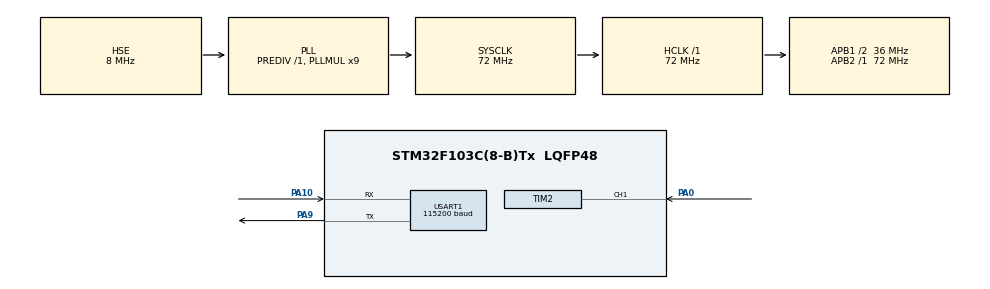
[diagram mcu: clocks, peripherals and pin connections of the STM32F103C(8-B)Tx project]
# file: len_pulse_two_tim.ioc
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Mcu.Family=STM32F1
Mcu.Name=STM32F103C(8-B)Tx
Mcu.Package=LQFP48
NVIC.PriorityGroup=NVIC_PRIORITYGROUP_4
NVIC.TIM2_IRQn=true\:0\:0\:false\:false\:true\:true
PA0-WKUP.Signal=S_TIM2_CH1_ETR
PA10.Mode=Asynchronous
PA10.Signal=USART1_RX
PA13.Mode=Serial_Wire
PA13.Signal=SYS_JTMS-SWDIO
PA14.Mode=Serial_Wire
PA14.Signal=SYS_JTCK-SWCLK
PA9.Mode=Asynchronous
PA9.Signal=USART1_TX
PD0-OSC_IN.Mode=HSE-External-Oscillator
PD0-OSC_IN.Signal=RCC_OSC_IN
PD1-OSC_OUT.Mode=HSE-External-Oscillator
PD1-OSC_OUT.Signal=RCC_OSC_OUT
ProjectManager.HeapSize=0x200
ProjectManager.StackSize=0x400
ProjectManager.TargetToolchain=TrueSTUDIO
RCC.AHBFreq_Value=72000000
RCC.APB1CLKDivider=RCC_HCLK_DIV2
RCC.APB1Freq_Value=36000000
RCC.APB1TimFreq_Value=72000000
RCC.APB2Freq_Value=72000000
RCC.APB2TimFreq_Value=72000000
RCC.HCLKFreq_Value=72000000
RCC.PLLMUL=RCC_PLL_MUL9
RCC.PLLSourceVirtual=RCC_PLLSOURCE_HSE
RCC.SYSCLKFreq_VALUE=72000000
RCC.SYSCLKSource=RCC_SYSCLKSOURCE_PLLCLK
RCC.USBFreq_Value=72000000
SH.S_TIM2_CH1_ETR.0=TIM2_CH1,Input_Capture1_from_TI1
SH.S_TIM2_CH1_ETR.1=TIM2_CH1,Input_Capture2_from_TI1
SH.S_TIM2_CH1_ETR.2=TIM2_CH1,TriggerSource_TI1FP1
TIM2.Channel-Input_Capture1_from_TI1=TIM_CHANNEL_1
TIM2.Channel-Input_Capture2_from_TI1=TIM_CHANNEL_2
TIM2.ICPolarity_CH2=TIM_INPUTCHANNELPOLARITY_FALLING
TIM2.Period=65000
TIM2.Prescaler=72
TIM2.TIM_MasterOutputTrigger=TIM_TRGO_UPDATE
TIM3.Period=65535
USART1.BaudRate=115200
USART1.VirtualMode=VM_ASYNC
VP_TIM2_VS_ControllerModeReset.Mode=Reset Mode
VP_TIM3_VS_ClockSourceITR.Mode=TriggerSource_ITR1
VP_TIM3_VS_ControllerModeClock.Mode=Clock Mode
board=custom

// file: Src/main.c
/* USER CODE BEGIN Header */
/**
  ******************************************************************************
  * @file           : main.c
  * @brief          : Main program body
  ******************************************************************************
  ** This notice applies to any and all portions of this file
  * that are not between comment pairs USER CODE BEGIN and
  * USER CODE END. Other portions of this file, whether
  * inserted by the user or by software development tools
  * are owned by their respective copyright owners.
  *
  * COPYRIGHT(c) 2019 STMicroelectronics
  *
  * Redistribution and use in source and binary forms, with or without modification,
  * are permitted provided that the following conditions are met:
  *   1. Redistributions of source code must retain the above copyright notice,
  *      this list of conditions and the following disclaimer.
  *   2. Redistributions in binary form must reproduce the above copyright notice,
  *      this list of conditions and the following disclaimer in the documentation
  *      and/or other materials provided with the distribution.
  *   3. Neither the name of STMicroelectronics nor the names of its contributors
  *      may be used to endorse or promote products derived from this software
  *      without specific prior written permission.
  *
  * THIS SOFTWARE IS PROVIDED BY THE COPYRIGHT HOLDERS AND CONTRIBUTORS "AS IS"
  * AND ANY EXPRESS OR IMPLIED WARRANTIES, INCLUDING, BUT NOT LIMITED TO, THE
  * IMPLIED WARRANTIES OF MERCHANTABILITY AND FITNESS FOR A PARTICULAR PURPOSE ARE
  * DISCLAIMED. IN NO EVENT SHALL THE COPYRIGHT HOLDER OR CONTRIBUTORS BE LIABLE
  * FOR ANY DIRECT, INDIRECT, INCIDENTAL, SPECIAL, EXEMPLARY, OR CONSEQUENTIAL
  * DAMAGES (INCLUDING, BUT NOT LIMITED TO, PROCUREMENT OF SUBSTITUTE GOODS OR
  * SERVICES; LOSS OF USE, DATA, OR PROFITS; OR BUSINESS INTERRUPTION) HOWEVER
  * CAUSED AND ON ANY THEORY OF LIABILITY, WHETHER IN CONTRACT, STRICT LIABILITY,
  * OR TORT (INCLUDING NEGLIGENCE OR OTHERWISE) ARISING IN ANY WAY OUT OF THE USE
  * OF THIS SOFTWARE, EVEN IF ADVISED OF THE POSSIBILITY OF SUCH DAMAGE.
  *
  ******************************************************************************
  */
/* USER CODE END Header */

#include "main.h"

/* USER CODE BEGIN Includes */
#include "string.h"
/* USER CODE END Includes */

TIM_HandleTypeDef htim2;
TIM_HandleTypeDef htim3;

UART_HandleTypeDef huart1;

/* USER CODE BEGIN PV */
char trans_str[32] = {0,};
/* USER CODE END PV */

void SystemClock_Config(void);
static void MX_GPIO_Init(void);
static void MX_USART1_UART_Init(void);
static void MX_TIM3_Init(void);
static void MX_TIM2_Init(void);

/* USER CODE BEGIN 0 */

////////////// счётный регистр таймера №3 используется как счётчик переполнений таймера №2 ////////////////

void HAL_TIM_IC_CaptureCallback(TIM_HandleTypeDef *htim)
{
	if(htim->Instance == TIM2) // pulse channel 1 2
	{
		if(htim->Channel == HAL_TIM_ACTIVE_CHANNEL_1) // RISING с LOW на HIGH
		{
			//__HAL_TIM_SET_COUNTER(&htim2, 0x0000); // таймер №2 обнуляется по тригеру TI1FP1 (см. в CubeMX)
			__HAL_TIM_SET_COUNTER(&htim3, 0x0000);
		}

		else if(htim->Channel == HAL_TIM_ACTIVE_CHANNEL_2) // FALLING с HIGH на LOW
		{
			uint32_t faling = HAL_TIM_ReadCapturedValue(&htim2, TIM_CHANNEL_2);
			snprintf(trans_str, 31, "Pulse_12 %lu\n", faling + (__HAL_TIM_GET_AUTORELOAD(&htim2) * __HAL_TIM_GET_COUNTER(&htim3)));
			HAL_UART_Transmit(&huart1, (uint8_t*)trans_str, strlen(trans_str), 1000);

			snprintf(trans_str, 31, "ETR_T3 %lu\n", __HAL_TIM_GET_COUNTER(&htim3));
			HAL_UART_Transmit(&huart1, (uint8_t*)trans_str, strlen(trans_str), 1000);
		}
	}
}
/* USER CODE END 0 */

int main(void)
{

  /* MCU Configuration--------------------------------------------------------*/

  /* Reset of all peripherals, Initializes the Flash interface and the Systick. */
  HAL_Init();

  /* Configure the system clock */
  SystemClock_Config();

  /* Initialize all configured peripherals */
  MX_GPIO_Init();
  MX_USART1_UART_Init();
  MX_TIM3_Init();
  MX_TIM2_Init();
  /* USER CODE BEGIN 2 */
  HAL_TIM_Base_Start(&htim2);
  HAL_TIM_IC_Start_IT(&htim2, TIM_CHANNEL_1);
  HAL_TIM_IC_Start_IT(&htim2, TIM_CHANNEL_2);
  HAL_TIM_Base_Start(&htim3);
  /* USER CODE END 2 */

  /* Infinite loop */
  while (1)
  {

  }
}

void SystemClock_Config(void)
{
  RCC_OscInitTypeDef RCC_OscInitStruct = {0};
  RCC_ClkInitTypeDef RCC_ClkInitStruct = {0};

  /**Initializes the CPU, AHB and APB busses clocks
  */
  RCC_OscInitStruct.OscillatorType = RCC_OSCILLATORTYPE_HSE;
  RCC_OscInitStruct.HSEState = RCC_HSE_ON;
  RCC_OscInitStruct.HSEPredivValue = RCC_HSE_PREDIV_DIV1;
  RCC_OscInitStruct.HSIState = RCC_HSI_ON;
  RCC_OscInitStruct.PLL.PLLState = RCC_PLL_ON;
  RCC_OscInitStruct.PLL.PLLSource = RCC_PLLSOURCE_HSE;
  RCC_OscInitStruct.PLL.PLLMUL = RCC_PLL_MUL9;
  if (HAL_RCC_OscConfig(&RCC_OscInitStruct) != HAL_OK)
  {
    Error_Handler();
  }
  /**Initializes the CPU, AHB and APB busses clocks
  */
  RCC_ClkInitStruct.ClockType = RCC_CLOCKTYPE_HCLK|RCC_CLOCKTYPE_SYSCLK
                              |RCC_CLOCKTYPE_PCLK1|RCC_CLOCKTYPE_PCLK2;
  RCC_ClkInitStruct.SYSCLKSource = RCC_SYSCLKSOURCE_PLLCLK;
  RCC_ClkInitStruct.AHBCLKDivider = RCC_SYSCLK_DIV1;
  RCC_ClkInitStruct.APB1CLKDivider = RCC_HCLK_DIV2;
  RCC_ClkInitStruct.APB2CLKDivider = RCC_HCLK_DIV1;

  if (HAL_RCC_ClockConfig(&RCC_ClkInitStruct, FLASH_LATENCY_2) != HAL_OK)
  {
    Error_Handler();
  }
}

static void MX_TIM2_Init(void)
{

  TIM_SlaveConfigTypeDef sSlaveConfig = {0};
  TIM_MasterConfigTypeDef sMasterConfig = {0};
  TIM_IC_InitTypeDef sConfigIC = {0};

  htim2.Instance = TIM2;
  htim2.Init.Prescaler = 72;
  htim2.Init.CounterMode = TIM_COUNTERMODE_UP;
  htim2.Init.Period = 65000;
  htim2.Init.ClockDivision = TIM_CLOCKDIVISION_DIV1;
  htim2.Init.AutoReloadPreload = TIM_AUTORELOAD_PRELOAD_DISABLE;
  if (HAL_TIM_Base_Init(&htim2) != HAL_OK)
  {
    Error_Handler();
  }
  if (HAL_TIM_IC_Init(&htim2) != HAL_OK)
  {
    Error_Handler();
  }
  sSlaveConfig.SlaveMode = TIM_SLAVEMODE_RESET;
  sSlaveConfig.InputTrigger = TIM_TS_TI1FP1;
  sSlaveConfig.TriggerPolarity = TIM_INPUTCHANNELPOLARITY_RISING;
  sSlaveConfig.TriggerFilter = 0;
  if (HAL_TIM_SlaveConfigSynchronization(&htim2, &sSlaveConfig) != HAL_OK)
  {
    Error_Handler();
  }
  sMasterConfig.MasterOutputTrigger = TIM_TRGO_UPDATE;
  sMasterConfig.MasterSlaveMode = TIM_MASTERSLAVEMODE_DISABLE;
  if (HAL_TIMEx_MasterConfigSynchronization(&htim2, &sMasterConfig) != HAL_OK)
  {
    Error_Handler();
  }
  sConfigIC.ICPolarity = TIM_INPUTCHANNELPOLARITY_RISING;
  sConfigIC.ICSelection = TIM_ICSELECTION_DIRECTTI;
  sConfigIC.ICPrescaler = TIM_ICPSC_DIV1;
  sConfigIC.ICFilter = 0;
  if (HAL_TIM_IC_ConfigChannel(&htim2, &sConfigIC, TIM_CHANNEL_1) != HAL_OK)
  {
    Error_Handler();
  }
  sConfigIC.ICPolarity = TIM_INPUTCHANNELPOLARITY_FALLING;
  sConfigIC.ICSelection = TIM_ICSELECTION_INDIRECTTI;
  if (HAL_TIM_IC_ConfigChannel(&htim2, &sConfigIC, TIM_CHANNEL_2) != HAL_OK)
  {
    Error_Handler();
  }

}

static void MX_TIM3_Init(void)
{

  TIM_SlaveConfigTypeDef sSlaveConfig = {0};
  TIM_MasterConfigTypeDef sMasterConfig = {0};

  htim3.Instance = TIM3;
  htim3.Init.Prescaler = 0;
  htim3.Init.CounterMode = TIM_COUNTERMODE_UP;
  htim3.Init.Period = 65535;
  htim3.Init.ClockDivision = TIM_CLOCKDIVISION_DIV1;
  htim3.Init.AutoReloadPreload = TIM_AUTORELOAD_PRELOAD_DISABLE;
  if (HAL_TIM_Base_Init(&htim3) != HAL_OK)
  {
    Error_Handler();
  }
  sSlaveConfig.SlaveMode = TIM_SLAVEMODE_EXTERNAL1;
  sSlaveConfig.InputTrigger = TIM_TS_ITR1;
  if (HAL_TIM_SlaveConfigSynchronization(&htim3, &sSlaveConfig) != HAL_OK)
  {
    Error_Handler();
  }
  sMasterConfig.MasterOutputTrigger = TIM_TRGO_RESET;
  sMasterConfig.MasterSlaveMode = TIM_MASTERSLAVEMODE_DISABLE;
  if (HAL_TIMEx_MasterConfigSynchronization(&htim3, &sMasterConfig) != HAL_OK)
  {
    Error_Handler();
  }

}

static void MX_USART1_UART_Init(void)
{

  huart1.Instance = USART1;
  huart1.Init.BaudRate = 115200;
  huart1.Init.WordLength = UART_WORDLENGTH_8B;
  huart1.Init.StopBits = UART_STOPBITS_1;
  huart1.Init.Parity = UART_PARITY_NONE;
  huart1.Init.Mode = UART_MODE_TX_RX;
  huart1.Init.HwFlowCtl = UART_HWCONTROL_NONE;
  huart1.Init.OverSampling = UART_OVERSAMPLING_16;
  if (HAL_UART_Init(&huart1) != HAL_OK)
  {
    Error_Handler();
  }

}

static void MX_GPIO_Init(void)
{

  /* GPIO Ports Clock Enable */
  __HAL_RCC_GPIOD_CLK_ENABLE();
  __HAL_RCC_GPIOA_CLK_ENABLE();

}

void Error_Handler(void)
{
}

/************************ (C) COPYRIGHT STMicroelectronics *****END OF FILE****/
